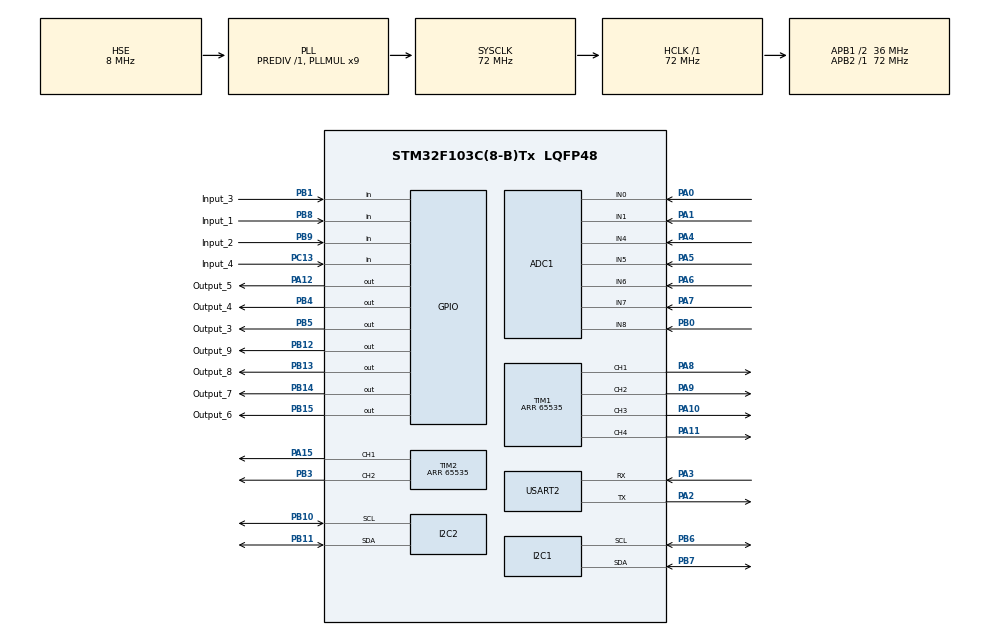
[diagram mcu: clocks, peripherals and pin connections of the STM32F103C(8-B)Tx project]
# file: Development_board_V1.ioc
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ADC1.Channel-0\#ChannelRegularConversion=ADC_CHANNEL_0
ADC1.Channel-1\#ChannelRegularConversion=ADC_CHANNEL_1
ADC1.Channel-2\#ChannelRegularConversion=ADC_CHANNEL_4
ADC1.Channel-3\#ChannelRegularConversion=ADC_CHANNEL_5
ADC1.Channel-4\#ChannelRegularConversion=ADC_CHANNEL_6
ADC1.Channel-5\#ChannelRegularConversion=ADC_CHANNEL_7
ADC1.Channel-6\#ChannelRegularConversion=ADC_CHANNEL_8
ADC1.ContinuousConvMode=ENABLE
ADC1.NbrOfConversion=7
ADC1.NbrOfConversionFlag=1
ADC1.Rank-0\#ChannelRegularConversion=1
ADC1.Rank-1\#ChannelRegularConversion=2
ADC1.Rank-2\#ChannelRegularConversion=3
ADC1.Rank-3\#ChannelRegularConversion=4
ADC1.Rank-4\#ChannelRegularConversion=5
ADC1.Rank-5\#ChannelRegularConversion=6
ADC1.Rank-6\#ChannelRegularConversion=7
ADC1.SamplingTime-0\#ChannelRegularConversion=ADC_SAMPLETIME_1CYCLE_5
ADC1.SamplingTime-1\#ChannelRegularConversion=ADC_SAMPLETIME_1CYCLE_5
ADC1.SamplingTime-2\#ChannelRegularConversion=ADC_SAMPLETIME_1CYCLE_5
ADC1.SamplingTime-3\#ChannelRegularConversion=ADC_SAMPLETIME_1CYCLE_5
ADC1.SamplingTime-4\#ChannelRegularConversion=ADC_SAMPLETIME_1CYCLE_5
ADC1.SamplingTime-5\#ChannelRegularConversion=ADC_SAMPLETIME_1CYCLE_5
ADC1.SamplingTime-6\#ChannelRegularConversion=ADC_SAMPLETIME_1CYCLE_5
ADC1.master=1
Dma.ADC1.0.Direction=DMA_PERIPH_TO_MEMORY
Dma.ADC1.0.Instance=DMA1_Channel1
Dma.ADC1.0.MemDataAlignment=DMA_MDATAALIGN_WORD
Dma.ADC1.0.MemInc=DMA_MINC_ENABLE
Dma.ADC1.0.Mode=DMA_CIRCULAR
Dma.ADC1.0.PeriphDataAlignment=DMA_PDATAALIGN_WORD
Dma.ADC1.0.PeriphInc=DMA_PINC_DISABLE
Dma.ADC1.0.Priority=DMA_PRIORITY_LOW
Dma.Request0=ADC1
Mcu.Family=STM32F1
Mcu.Name=STM32F103C(8-B)Tx
Mcu.Package=LQFP48
NVIC.DMA1_Channel1_IRQn=true\:0\:0\:false\:false\:true\:false\:true
NVIC.PriorityGroup=NVIC_PRIORITYGROUP_4
PA0-WKUP.Signal=ADCx_IN0
PA1.Signal=ADCx_IN1
PA10.Signal=S_TIM1_CH3
PA11.Signal=S_TIM1_CH4
PA12.GPIO_Label=Output_5
PA12.Signal=GPIO_Output
PA13.Mode=Serial_Wire
PA13.Signal=SYS_JTMS-SWDIO
PA14.Mode=Serial_Wire
PA14.Signal=SYS_JTCK-SWCLK
PA15.Signal=S_TIM2_CH1_ETR
PA2.Mode=Asynchronous
PA2.Signal=USART2_TX
PA3.Mode=Asynchronous
PA3.Signal=USART2_RX
PA4.Signal=ADCx_IN4
PA5.Signal=ADCx_IN5
PA6.Signal=ADCx_IN6
PA7.Signal=ADCx_IN7
PA8.Signal=S_TIM1_CH1
PA9.Signal=S_TIM1_CH2
PB0.Signal=ADCx_IN8
PB1.GPIO_Label=Input_3
PB1.Signal=GPIO_Input
PB10.Mode=I2C
PB10.Signal=I2C2_SCL
PB11.Mode=I2C
PB11.Signal=I2C2_SDA
PB12.GPIO_Label=Output_9
PB12.Signal=GPIO_Output
PB13.GPIO_Label=Output_8
PB13.Signal=GPIO_Output
PB14.GPIO_Label=Output_7
PB14.Signal=GPIO_Output
PB15.GPIO_Label=Output_6
PB15.Signal=GPIO_Output
PB3.Signal=S_TIM2_CH2
PB4.GPIO_Label=Output_4
PB4.Signal=GPIO_Output
PB5.GPIO_Label=Output_3
PB5.Signal=GPIO_Output
PB6.Mode=I2C
PB6.Signal=I2C1_SCL
PB7.Mode=I2C
PB7.Signal=I2C1_SDA
PB8.GPIO_Label=Input_1
PB8.Signal=GPIO_Input
PB9.GPIO_Label=Input_2
PB9.Signal=GPIO_Input
PC13-TAMPER-RTC.GPIO_Label=Input_4
PC13-TAMPER-RTC.Signal=GPIO_Input
PC14-OSC32_IN.Signal=RCC_OSC32_IN
PC15-OSC32_OUT.Signal=RCC_OSC32_OUT
PD0-OSC_IN.Mode=HSE-External-Oscillator
PD0-OSC_IN.Signal=RCC_OSC_IN
PD1-OSC_OUT.Mode=HSE-External-Oscillator
PD1-OSC_OUT.Signal=RCC_OSC_OUT
ProjectManager.HeapSize=0x200
ProjectManager.StackSize=0x400
ProjectManager.TargetToolchain=STM32CubeIDE
RCC.ADCPresc=RCC_ADCPCLK2_DIV6
RCC.AHBFreq_Value=72000000
RCC.APB1CLKDivider=RCC_HCLK_DIV2
RCC.APB1Freq_Value=36000000
RCC.APB1TimFreq_Value=72000000
RCC.APB2Freq_Value=72000000
RCC.APB2TimFreq_Value=72000000
RCC.HCLKFreq_Value=72000000
RCC.PLLMUL=RCC_PLL_MUL9
RCC.PLLSourceVirtual=RCC_PLLSOURCE_HSE
RCC.SYSCLKFreq_VALUE=72000000
RCC.SYSCLKSource=RCC_SYSCLKSOURCE_PLLCLK
RCC.USBFreq_Value=72000000
SH.ADCx_IN0.0=ADC1_IN0,IN0
SH.ADCx_IN1.0=ADC1_IN1,IN1
SH.ADCx_IN4.0=ADC1_IN4,IN4
SH.ADCx_IN5.0=ADC1_IN5,IN5
SH.ADCx_IN6.0=ADC1_IN6,IN6
SH.ADCx_IN7.0=ADC1_IN7,IN7
SH.ADCx_IN8.0=ADC1_IN8,IN8
SH.S_TIM1_CH1.0=TIM1_CH1,PWM Generation1 CH1
SH.S_TIM1_CH2.0=TIM1_CH2,PWM Generation2 CH2
SH.S_TIM1_CH3.0=TIM1_CH3,PWM Generation3 CH3
SH.S_TIM1_CH4.0=TIM1_CH4,PWM Generation4 CH4
SH.S_TIM2_CH1_ETR.0=TIM2_CH1,PWM Generation1 CH1
SH.S_TIM2_CH2.0=TIM2_CH2,PWM Generation2 CH2
TIM1.Channel-PWM\ Generation1\ CH1=TIM_CHANNEL_1
TIM1.Channel-PWM\ Generation2\ CH2=TIM_CHANNEL_2
TIM1.Channel-PWM\ Generation3\ CH3=TIM_CHANNEL_3
TIM1.Channel-PWM\ Generation4\ CH4=TIM_CHANNEL_4
TIM1.Period=65535
TIM2.Channel-PWM\ Generation1\ CH1=TIM_CHANNEL_1
TIM2.Channel-PWM\ Generation2\ CH2=TIM_CHANNEL_2
TIM2.Period=65535
USART2.VirtualMode=VM_ASYNC
VP_TIM1_VS_ClockSourceINT.Mode=Internal
board=custom

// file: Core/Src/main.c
/* USER CODE BEGIN Header */
/**
  ******************************************************************************
  * @file           : main.c
  * @brief          : Main program body
  ******************************************************************************
  * @attention
  *
  * <h2><center>&copy; Copyright (c) 2020 STMicroelectronics.
  * All rights reserved.</center></h2>
  *
  * This software component is licensed by ST under BSD 3-Clause license,
  * the "License"; You may not use this file except in compliance with the
  * License. You may obtain a copy of the License at:
  *                        opensource.org/licenses/BSD-3-Clause
  *
  ******************************************************************************
  */
/* USER CODE END Header */

#include "main.h"
#include "i2c-lcd.h"

ADC_HandleTypeDef hadc1;
DMA_HandleTypeDef hdma_adc1;

I2C_HandleTypeDef hi2c1;
I2C_HandleTypeDef hi2c2;

TIM_HandleTypeDef htim1;
TIM_HandleTypeDef htim2;

UART_HandleTypeDef huart2;

void SystemClock_Config(void);
static void MX_GPIO_Init(void);
static void MX_DMA_Init(void);
static void MX_ADC1_Init(void);
static void MX_I2C1_Init(void);
static void MX_I2C2_Init(void);
static void MX_TIM1_Init(void);
static void MX_TIM2_Init(void);
static void MX_USART2_UART_Init(void);

/* USER CODE BEGIN 0 */
uint32_t value[3];  // to store the adc values
float temp;  // temperature
// let's get the values from the datasheet
#define V25  1.43
#define Avg_Slope .0043
#define VSENSE 3.3/4096   // 3.3 v and 12 bits so 4096

float get_temp (uint32_t variable)   // function to read temp from the value
{
	return (((V25 - VSENSE*variable) / Avg_Slope) + 25);
}
/* USER CODE END 0 */

int main(void)
{

  /* MCU Configuration--------------------------------------------------------*/

  /* Reset of all peripherals, Initializes the Flash interface and the Systick. */
  HAL_Init();

  /* Configure the system clock */
  SystemClock_Config();

  /* Initialize all configured peripherals */
  MX_GPIO_Init();
  MX_DMA_Init();
  MX_ADC1_Init();
  MX_I2C1_Init();
  MX_I2C2_Init();
  MX_TIM1_Init();
  MX_TIM2_Init();
  MX_USART2_UART_Init();
  /* USER CODE BEGIN 2 */
  lcd_init ();  // initialise the LCD

  HAL_ADC_Start_DMA(&hadc1, value, 3);  // start the adc in dma mode
  /* USER CODE END 2 */
lcd_clear();
HAL_Delay(1000);
  /* Infinite loop */
  while (1)
  {
	  lcd_send_cmd (0x80);  // position 00
	  lcd_send_string ("CH0- ");  // send string
	  lcd_send_data ((value[0]/1000)+48);  // print the 1000th value of value[0]
	  lcd_send_data (((value[0]%1000)/100)+48);  // print the 100th value of value[0]
	  lcd_send_data (((value[0]%100)/10)+48);  // print the 10th value of value[0]
	  lcd_send_data (((value[0]%10))+48);  // print the 1st value of value[0]

	  //print value[1]
	  lcd_send_cmd (0x8b);
	  lcd_send_string ("CH1- ");
	  lcd_send_cmd (0xc0);
	  lcd_send_data((value[1]/1000)+48);  // print 1000th digit
	  lcd_send_data(((value[1]%1000)/100)+48);  //print 100th digit
	  lcd_send_data(((value[1]%100)/10)+48);  //print 10th digit
	  lcd_send_data(((value[1]%10))+48);  //print 1st digit

	  // print temp
	  temp = get_temp(value[2]);
	  lcd_send_string (" TEMP- ");
	  lcd_send_data ((temp/10)+48);
	  lcd_send_data (((int )temp%10)+48);
	  lcd_send_data ('.');
	  lcd_send_data (((int )(temp*10)%10)+48);
	  lcd_send_data('C');

	  HAL_Delay (200); // 200ms delay
  }
}

void SystemClock_Config(void)
{
  RCC_OscInitTypeDef RCC_OscInitStruct = {0};
  RCC_ClkInitTypeDef RCC_ClkInitStruct = {0};
  RCC_PeriphCLKInitTypeDef PeriphClkInit = {0};

  /** Initializes the CPU, AHB and APB busses clocks
  */
  RCC_OscInitStruct.OscillatorType = RCC_OSCILLATORTYPE_HSE;
  RCC_OscInitStruct.HSEState = RCC_HSE_ON;
  RCC_OscInitStruct.HSEPredivValue = RCC_HSE_PREDIV_DIV1;
  RCC_OscInitStruct.HSIState = RCC_HSI_ON;
  RCC_OscInitStruct.PLL.PLLState = RCC_PLL_ON;
  RCC_OscInitStruct.PLL.PLLSource = RCC_PLLSOURCE_HSE;
  RCC_OscInitStruct.PLL.PLLMUL = RCC_PLL_MUL9;
  if (HAL_RCC_OscConfig(&RCC_OscInitStruct) != HAL_OK)
  {
    Error_Handler();
  }
  /** Initializes the CPU, AHB and APB busses clocks
  */
  RCC_ClkInitStruct.ClockType = RCC_CLOCKTYPE_HCLK|RCC_CLOCKTYPE_SYSCLK
                              |RCC_CLOCKTYPE_PCLK1|RCC_CLOCKTYPE_PCLK2;
  RCC_ClkInitStruct.SYSCLKSource = RCC_SYSCLKSOURCE_PLLCLK;
  RCC_ClkInitStruct.AHBCLKDivider = RCC_SYSCLK_DIV1;
  RCC_ClkInitStruct.APB1CLKDivider = RCC_HCLK_DIV2;
  RCC_ClkInitStruct.APB2CLKDivider = RCC_HCLK_DIV1;

  if (HAL_RCC_ClockConfig(&RCC_ClkInitStruct, FLASH_LATENCY_2) != HAL_OK)
  {
    Error_Handler();
  }
  PeriphClkInit.PeriphClockSelection = RCC_PERIPHCLK_ADC;
  PeriphClkInit.AdcClockSelection = RCC_ADCPCLK2_DIV6;
  if (HAL_RCCEx_PeriphCLKConfig(&PeriphClkInit) != HAL_OK)
  {
    Error_Handler();
  }
}

static void MX_ADC1_Init(void)
{

  ADC_ChannelConfTypeDef sConfig = {0};

  /** Common config
  */
  hadc1.Instance = ADC1;
  hadc1.Init.ScanConvMode = ADC_SCAN_ENABLE;
  hadc1.Init.ContinuousConvMode = ENABLE;
  hadc1.Init.DiscontinuousConvMode = DISABLE;
  hadc1.Init.ExternalTrigConv = ADC_SOFTWARE_START;
  hadc1.Init.DataAlign = ADC_DATAALIGN_RIGHT;
  hadc1.Init.NbrOfConversion = 7;
  if (HAL_ADC_Init(&hadc1) != HAL_OK)
  {
    Error_Handler();
  }
  /** Configure Regular Channel
  */
  sConfig.Channel = ADC_CHANNEL_0;
  sConfig.Rank = ADC_REGULAR_RANK_1;
  sConfig.SamplingTime = ADC_SAMPLETIME_1CYCLE_5;
  if (HAL_ADC_ConfigChannel(&hadc1, &sConfig) != HAL_OK)
  {
    Error_Handler();
  }
  /** Configure Regular Channel
  */
  sConfig.Channel = ADC_CHANNEL_1;
  sConfig.Rank = ADC_REGULAR_RANK_2;
  if (HAL_ADC_ConfigChannel(&hadc1, &sConfig) != HAL_OK)
  {
    Error_Handler();
  }
  /** Configure Regular Channel
  */
  sConfig.Channel = ADC_CHANNEL_4;
  sConfig.Rank = ADC_REGULAR_RANK_3;
  if (HAL_ADC_ConfigChannel(&hadc1, &sConfig) != HAL_OK)
  {
    Error_Handler();
  }
  /** Configure Regular Channel
  */
  sConfig.Channel = ADC_CHANNEL_5;
  sConfig.Rank = ADC_REGULAR_RANK_4;
  if (HAL_ADC_ConfigChannel(&hadc1, &sConfig) != HAL_OK)
  {
    Error_Handler();
  }
  /** Configure Regular Channel
  */
  sConfig.Channel = ADC_CHANNEL_6;
  sConfig.Rank = ADC_REGULAR_RANK_5;
  if (HAL_ADC_ConfigChannel(&hadc1, &sConfig) != HAL_OK)
  {
    Error_Handler();
  }
  /** Configure Regular Channel
  */
  sConfig.Channel = ADC_CHANNEL_7;
  sConfig.Rank = ADC_REGULAR_RANK_6;
  if (HAL_ADC_ConfigChannel(&hadc1, &sConfig) != HAL_OK)
  {
    Error_Handler();
  }
  /** Configure Regular Channel
  */
  sConfig.Channel = ADC_CHANNEL_8;
  sConfig.Rank = ADC_REGULAR_RANK_7;
  if (HAL_ADC_ConfigChannel(&hadc1, &sConfig) != HAL_OK)
  {
    Error_Handler();
  }

}

static void MX_I2C1_Init(void)
{

  hi2c1.Instance = I2C1;
  hi2c1.Init.ClockSpeed = 100000;
  hi2c1.Init.DutyCycle = I2C_DUTYCYCLE_2;
  hi2c1.Init.OwnAddress1 = 0;
  hi2c1.Init.AddressingMode = I2C_ADDRESSINGMODE_7BIT;
  hi2c1.Init.DualAddressMode = I2C_DUALADDRESS_DISABLE;
  hi2c1.Init.OwnAddress2 = 0;
  hi2c1.Init.GeneralCallMode = I2C_GENERALCALL_DISABLE;
  hi2c1.Init.NoStretchMode = I2C_NOSTRETCH_DISABLE;
  if (HAL_I2C_Init(&hi2c1) != HAL_OK)
  {
    Error_Handler();
  }

}

static void MX_I2C2_Init(void)
{

  hi2c2.Instance = I2C2;
  hi2c2.Init.ClockSpeed = 100000;
  hi2c2.Init.DutyCycle = I2C_DUTYCYCLE_2;
  hi2c2.Init.OwnAddress1 = 0;
  hi2c2.Init.AddressingMode = I2C_ADDRESSINGMODE_7BIT;
  hi2c2.Init.DualAddressMode = I2C_DUALADDRESS_DISABLE;
  hi2c2.Init.OwnAddress2 = 0;
  hi2c2.Init.GeneralCallMode = I2C_GENERALCALL_DISABLE;
  hi2c2.Init.NoStretchMode = I2C_NOSTRETCH_DISABLE;
  if (HAL_I2C_Init(&hi2c2) != HAL_OK)
  {
    Error_Handler();
  }

}

static void MX_TIM1_Init(void)
{

  TIM_ClockConfigTypeDef sClockSourceConfig = {0};
  TIM_MasterConfigTypeDef sMasterConfig = {0};
  TIM_OC_InitTypeDef sConfigOC = {0};
  TIM_BreakDeadTimeConfigTypeDef sBreakDeadTimeConfig = {0};

  htim1.Instance = TIM1;
  htim1.Init.Prescaler = 0;
  htim1.Init.CounterMode = TIM_COUNTERMODE_UP;
  htim1.Init.Period = 65535;
  htim1.Init.ClockDivision = TIM_CLOCKDIVISION_DIV1;
  htim1.Init.RepetitionCounter = 0;
  htim1.Init.AutoReloadPreload = TIM_AUTORELOAD_PRELOAD_DISABLE;
  if (HAL_TIM_Base_Init(&htim1) != HAL_OK)
  {
    Error_Handler();
  }
  sClockSourceConfig.ClockSource = TIM_CLOCKSOURCE_INTERNAL;
  if (HAL_TIM_ConfigClockSource(&htim1, &sClockSourceConfig) != HAL_OK)
  {
    Error_Handler();
  }
  if (HAL_TIM_PWM_Init(&htim1) != HAL_OK)
  {
    Error_Handler();
  }
  sMasterConfig.MasterOutputTrigger = TIM_TRGO_RESET;
  sMasterConfig.MasterSlaveMode = TIM_MASTERSLAVEMODE_DISABLE;
  if (HAL_TIMEx_MasterConfigSynchronization(&htim1, &sMasterConfig) != HAL_OK)
  {
    Error_Handler();
  }
  sConfigOC.OCMode = TIM_OCMODE_PWM1;
  sConfigOC.Pulse = 0;
  sConfigOC.OCPolarity = TIM_OCPOLARITY_HIGH;
  sConfigOC.OCNPolarity = TIM_OCNPOLARITY_HIGH;
  sConfigOC.OCFastMode = TIM_OCFAST_DISABLE;
  sConfigOC.OCIdleState = TIM_OCIDLESTATE_RESET;
  sConfigOC.OCNIdleState = TIM_OCNIDLESTATE_RESET;
  if (HAL_TIM_PWM_ConfigChannel(&htim1, &sConfigOC, TIM_CHANNEL_1) != HAL_OK)
  {
    Error_Handler();
  }
  if (HAL_TIM_PWM_ConfigChannel(&htim1, &sConfigOC, TIM_CHANNEL_2) != HAL_OK)
  {
    Error_Handler();
  }
  if (HAL_TIM_PWM_ConfigChannel(&htim1, &sConfigOC, TIM_CHANNEL_3) != HAL_OK)
  {
    Error_Handler();
  }
  if (HAL_TIM_PWM_ConfigChannel(&htim1, &sConfigOC, TIM_CHANNEL_4) != HAL_OK)
  {
    Error_Handler();
  }
  sBreakDeadTimeConfig.OffStateRunMode = TIM_OSSR_DISABLE;
  sBreakDeadTimeConfig.OffStateIDLEMode = TIM_OSSI_DISABLE;
  sBreakDeadTimeConfig.LockLevel = TIM_LOCKLEVEL_OFF;
  sBreakDeadTimeConfig.DeadTime = 0;
  sBreakDeadTimeConfig.BreakState = TIM_BREAK_DISABLE;
  sBreakDeadTimeConfig.BreakPolarity = TIM_BREAKPOLARITY_HIGH;
  sBreakDeadTimeConfig.AutomaticOutput = TIM_AUTOMATICOUTPUT_DISABLE;
  if (HAL_TIMEx_ConfigBreakDeadTime(&htim1, &sBreakDeadTimeConfig) != HAL_OK)
  {
    Error_Handler();
  }
  HAL_TIM_MspPostInit(&htim1);

}

static void MX_TIM2_Init(void)
{

  TIM_MasterConfigTypeDef sMasterConfig = {0};
  TIM_OC_InitTypeDef sConfigOC = {0};

  htim2.Instance = TIM2;
  htim2.Init.Prescaler = 0;
  htim2.Init.CounterMode = TIM_COUNTERMODE_UP;
  htim2.Init.Period = 65535;
  htim2.Init.ClockDivision = TIM_CLOCKDIVISION_DIV1;
  htim2.Init.AutoReloadPreload = TIM_AUTORELOAD_PRELOAD_DISABLE;
  if (HAL_TIM_PWM_Init(&htim2) != HAL_OK)
  {
    Error_Handler();
  }
  sMasterConfig.MasterOutputTrigger = TIM_TRGO_RESET;
  sMasterConfig.MasterSlaveMode = TIM_MASTERSLAVEMODE_DISABLE;
  if (HAL_TIMEx_MasterConfigSynchronization(&htim2, &sMasterConfig) != HAL_OK)
  {
    Error_Handler();
  }
  sConfigOC.OCMode = TIM_OCMODE_PWM1;
  sConfigOC.Pulse = 0;
  sConfigOC.OCPolarity = TIM_OCPOLARITY_HIGH;
  sConfigOC.OCFastMode = TIM_OCFAST_DISABLE;
  if (HAL_TIM_PWM_ConfigChannel(&htim2, &sConfigOC, TIM_CHANNEL_1) != HAL_OK)
  {
    Error_Handler();
  }
  if (HAL_TIM_PWM_ConfigChannel(&htim2, &sConfigOC, TIM_CHANNEL_2) != HAL_OK)
  {
    Error_Handler();
  }
  HAL_TIM_MspPostInit(&htim2);

}

static void MX_USART2_UART_Init(void)
{

  huart2.Instance = USART2;
  huart2.Init.BaudRate = 115200;
  huart2.Init.WordLength = UART_WORDLENGTH_8B;
  huart2.Init.StopBits = UART_STOPBITS_1;
  huart2.Init.Parity = UART_PARITY_NONE;
  huart2.Init.Mode = UART_MODE_TX_RX;
  huart2.Init.HwFlowCtl = UART_HWCONTROL_NONE;
  huart2.Init.OverSampling = UART_OVERSAMPLING_16;
  if (HAL_UART_Init(&huart2) != HAL_OK)
  {
    Error_Handler();
  }

}

static void MX_DMA_Init(void)
{

  /* DMA controller clock enable */
  __HAL_RCC_DMA1_CLK_ENABLE();

  /* DMA interrupt init */
  /* DMA1_Channel1_IRQn interrupt configuration */
  HAL_NVIC_SetPriority(DMA1_Channel1_IRQn, 0, 0);
  HAL_NVIC_EnableIRQ(DMA1_Channel1_IRQn);

}

static void MX_GPIO_Init(void)
{
  GPIO_InitTypeDef GPIO_InitStruct = {0};

  /* GPIO Ports Clock Enable */
  __HAL_RCC_GPIOC_CLK_ENABLE();
  __HAL_RCC_GPIOD_CLK_ENABLE();
  __HAL_RCC_GPIOA_CLK_ENABLE();
  __HAL_RCC_GPIOB_CLK_ENABLE();

  /*Configure GPIO pin Output Level */
  HAL_GPIO_WritePin(GPIOB, Output_9_Pin|Output_8_Pin|Output_7_Pin|Output_6_Pin
                          |Output_4_Pin|Output_3_Pin, GPIO_PIN_RESET);

  /*Configure GPIO pin Output Level */
  HAL_GPIO_WritePin(Output_5_GPIO_Port, Output_5_Pin, GPIO_PIN_RESET);

  /*Configure GPIO pin : Input_4_Pin */
  GPIO_InitStruct.Pin = Input_4_Pin;
  GPIO_InitStruct.Mode = GPIO_MODE_INPUT;
  GPIO_InitStruct.Pull = GPIO_NOPULL;
  HAL_GPIO_Init(Input_4_GPIO_Port, &GPIO_InitStruct);

  /*Configure GPIO pins : Input_3_Pin Input_1_Pin Input_2_Pin */
  GPIO_InitStruct.Pin = Input_3_Pin|Input_1_Pin|Input_2_Pin;
  GPIO_InitStruct.Mode = GPIO_MODE_INPUT;
  GPIO_InitStruct.Pull = GPIO_NOPULL;
  HAL_GPIO_Init(GPIOB, &GPIO_InitStruct);

  /*Configure GPIO pins : Output_9_Pin Output_8_Pin Output_7_Pin Output_6_Pin
                           Output_4_Pin Output_3_Pin */
  GPIO_InitStruct.Pin = Output_9_Pin|Output_8_Pin|Output_7_Pin|Output_6_Pin
                          |Output_4_Pin|Output_3_Pin;
  GPIO_InitStruct.Mode = GPIO_MODE_OUTPUT_PP;
  GPIO_InitStruct.Pull = GPIO_NOPULL;
  GPIO_InitStruct.Speed = GPIO_SPEED_FREQ_LOW;
  HAL_GPIO_Init(GPIOB, &GPIO_InitStruct);

  /*Configure GPIO pin : Output_5_Pin */
  GPIO_InitStruct.Pin = Output_5_Pin;
  GPIO_InitStruct.Mode = GPIO_MODE_OUTPUT_PP;
  GPIO_InitStruct.Pull = GPIO_NOPULL;
  GPIO_InitStruct.Speed = GPIO_SPEED_FREQ_LOW;
  HAL_GPIO_Init(Output_5_GPIO_Port, &GPIO_InitStruct);

}

void Error_Handler(void)
{
}

/************************ (C) COPYRIGHT STMicroelectronics *****END OF FILE****/
